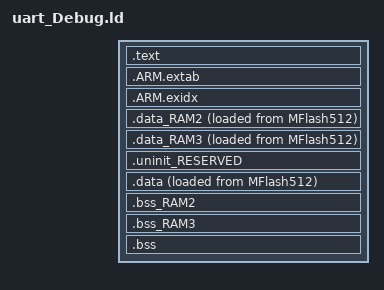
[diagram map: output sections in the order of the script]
/*
 * GENERATED FILE - DO NOT EDIT
 * (C) Code Red Technologies Ltd, 2008-2012
 * Generated linker script file for LPC1768
 * Created from generic_c.ld (vLPCXpresso v4.2 (4 [Build 267] [2012-07-11] ))
 * By LPCXpresso v4.2.4 [Build 267] [2012-07-11]  on Thu Sep 13 23:12:29 JST 2012
 */


INCLUDE "uart_Debug_lib.ld"
INCLUDE "uart_Debug_mem.ld"

ENTRY(ResetISR)

SECTIONS
{

	/* MAIN TEXT SECTION */	
	.text : ALIGN(4)
	{
		FILL(0xff)
		KEEP(*(.isr_vector))
		
		/* Global Section Table */
		. = ALIGN(4) ;
		__section_table_start = .;
		__data_section_table = .;
		LONG(LOADADDR(.data));
		LONG(    ADDR(.data)) ;
		LONG(  SIZEOF(.data));
		LONG(LOADADDR(.data_RAM2));
		LONG(    ADDR(.data_RAM2)) ;
		LONG(  SIZEOF(.data_RAM2));
		LONG(LOADADDR(.data_RAM3));
		LONG(    ADDR(.data_RAM3)) ;
		LONG(  SIZEOF(.data_RAM3));
		__data_section_table_end = .;
		__bss_section_table = .;
		LONG(    ADDR(.bss));
		LONG(  SIZEOF(.bss));
		LONG(    ADDR(.bss_RAM2));
		LONG(  SIZEOF(.bss_RAM2));
		LONG(    ADDR(.bss_RAM3));
		LONG(  SIZEOF(.bss_RAM3));
		__bss_section_table_end = .;
		__section_table_end = . ;
		/* End of Global Section Table */
		

		*(.after_vectors*)
		
		*(.text*)
		*(.rodata .rodata.*)
		. = ALIGN(4);
		
	} > MFlash512

	/*
	 * for exception handling/unwind - some Newlib functions (in common
	 * with C++ and STDC++) use this. 
	 * Use KEEP so not discarded with --gc-sections
	 */
	.ARM.extab : ALIGN(4)
	{
		KEEP(*(.ARM.extab* .gnu.linkonce.armextab.*))
	} > MFlash512
	__exidx_start = .;
	
	.ARM.exidx : ALIGN(4)
	{
		KEEP(*(.ARM.exidx* .gnu.linkonce.armexidx.*))
	} > MFlash512
	__exidx_end = .;
	
	_etext = .;
		
	
	.data_RAM2 : ALIGN(4)
	{
	   FILL(0xff)
		*(.data.$RAM2*)
		*(.data.$RamAHB32*)
	   . = ALIGN(4) ;
	} > RamAHB32 AT>MFlash512
	
	.data_RAM3 : ALIGN(4)
	{
	   FILL(0xff)
		*(.data.$RAM3*)
		*(.data.$CANAccFilterRAM*)
	   . = ALIGN(4) ;
	} > CANAccFilterRAM AT>MFlash512
	
	/* MAIN DATA SECTION */

	.uninit_RESERVED : ALIGN(4)
	{
		KEEP(*(.bss.$RESERVED*))
	} > RamLoc32

	.data : ALIGN(4)
	{
		FILL(0xff)
		_data = .;
		*(vtable)
		*(.data*)
		. = ALIGN(4) ;
		_edata = .;
	} > RamLoc32 AT>MFlash512

	
	.bss_RAM2 : ALIGN(4)
	{
		*(.bss.$RAM2*)
		*(.bss.$RamAHB32*)
	   . = ALIGN(4) ;
	} > RamAHB32
	
	.bss_RAM3 : ALIGN(4)
	{
		*(.bss.$RAM3*)
		*(.bss.$CANAccFilterRAM*)
	   . = ALIGN(4) ;
	} > CANAccFilterRAM

	/* MAIN BSS SECTION */
	.bss : ALIGN(4)
	{
		_bss = .;
		*(.bss*)
		*(COMMON)
		. = ALIGN(4) ;
		_ebss = .;
		PROVIDE(end = .);
	} > RamLoc32
	
	PROVIDE(_pvHeapStart = .);
	PROVIDE(_vStackTop = __top_RamLoc32 - 0);
}
